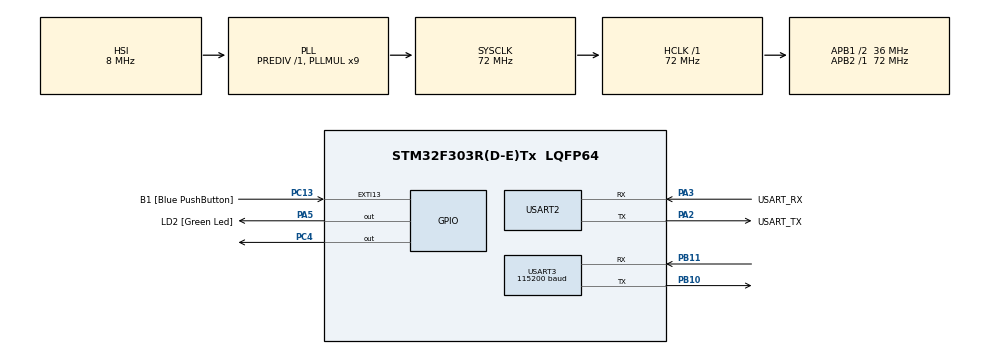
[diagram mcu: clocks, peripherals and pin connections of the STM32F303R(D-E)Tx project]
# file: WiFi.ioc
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Mcu.Family=STM32F3
Mcu.Name=STM32F303R(D-E)Tx
Mcu.Package=LQFP64
NVIC.PriorityGroup=NVIC_PRIORITYGROUP_0
NVIC.TIM1_TRG_COM_TIM17_IRQn=true\:0\:0\:false\:false\:true\:true\:true\:true
NVIC.USART3_IRQn=true\:0\:0\:false\:false\:true\:true\:true\:true
PA13.GPIO_Label=TMS
PA13.Mode=Serial_Wire
PA13.Signal=SYS_JTMS-SWDIO
PA14.GPIO_Label=TCK
PA14.Mode=Serial_Wire
PA14.Signal=SYS_JTCK-SWCLK
PA2.GPIO_Label=USART_TX
PA2.GPIO_Mode=GPIO_MODE_AF_PP
PA2.GPIO_PuPd=GPIO_NOPULL
PA2.GPIO_Speed=GPIO_SPEED_FREQ_LOW
PA2.Mode=Asynchronous
PA2.Signal=USART2_TX
PA3.GPIO_Label=USART_RX
PA3.GPIO_Mode=GPIO_MODE_AF_PP
PA3.GPIO_PuPd=GPIO_NOPULL
PA3.GPIO_Speed=GPIO_SPEED_FREQ_LOW
PA3.Mode=Asynchronous
PA3.Signal=USART2_RX
PA5.GPIO_Label=LD2 [Green Led]
PA5.GPIO_Mode=GPIO_MODE_OUTPUT_PP
PA5.GPIO_PuPd=GPIO_NOPULL
PA5.GPIO_Speed=GPIO_SPEED_FREQ_LOW
PA5.Signal=GPIO_Output
PB10.Mode=Asynchronous
PB10.Signal=USART3_TX
PB11.Mode=Asynchronous
PB11.Signal=USART3_RX
PB3.GPIO_Label=SWO
PB3.Signal=SYS_JTDO-TRACESWO
PC13.GPIO_Label=B1 [Blue PushButton]
PC13.GPIO_ModeDefaultEXTI=GPIO_MODE_IT_FALLING
PC13.Signal=GPXTI13
PC14-OSC32_IN.Mode=LSE-External-Oscillator
PC14-OSC32_IN.Signal=RCC_OSC32_IN
PC15-OSC32_OUT.Mode=LSE-External-Oscillator
PC15-OSC32_OUT.Signal=RCC_OSC32_OUT
PC4.GPIO_Speed=GPIO_SPEED_FREQ_HIGH
PC4.PinState=GPIO_PIN_SET
PC4.Signal=GPIO_Output
PF0-OSC_IN.Mode=HSE-External-Clock-Source
PF0-OSC_IN.Signal=RCC_OSC_IN
PF1-OSC_OUT.Signal=RCC_OSC_OUT
ProjectManager.HeapSize=0x200
ProjectManager.StackSize=0x400
ProjectManager.TargetToolchain=STM32CubeIDE
RCC.AHBFreq_Value=72000000
RCC.APB1CLKDivider=RCC_HCLK_DIV2
RCC.APB1Freq_Value=36000000
RCC.APB1TimFreq_Value=72000000
RCC.APB2Freq_Value=72000000
RCC.APB2TimFreq_Value=72000000
RCC.CortexFreq_Value=72000000
RCC.HCLKFreq_Value=72000000
RCC.HSE_VALUE=8000000
RCC.HSI_VALUE=8000000
RCC.PLLM=8
RCC.PLLMUL=RCC_PLL_MUL9
RCC.PLLN=336
RCC.PLLP=RCC_PLLP_DIV4
RCC.PLLQ=7
RCC.RCC_PLLsource_Clock_Source_FROM_HSE=RCC_HSE_PREDIV_DIV2
RCC.SYSCLKFreq_VALUE=72000000
RCC.SYSCLKSourceVirtual=RCC_SYSCLKSOURCE_PLLCLK
RCC.USBFreq_Value=72000000
TIM17.Period=59999
TIM17.Prescaler=11
USART2.VirtualMode-Asynchronous=VM_ASYNC
USART3.BaudRate=115200
USART3.VirtualMode-Asynchronous=VM_ASYNC
VP_TIM17_VS_ClockSourceINT.Mode=Enable_Timer
board=NUCLEO-F303RE

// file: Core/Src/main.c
/* USER CODE BEGIN Header */
/**
  ******************************************************************************
  * @file           : main.c
  * @brief          : Main program body
  ******************************************************************************
  * @attention
  *
  * Copyright (c) 2024 STMicroelectronics.
  * All rights reserved.
  *
  * This software is licensed under terms that can be found in the LICENSE file
  * in the root directory of this software component.
  * If no LICENSE file comes with this software, it is provided AS-IS.
  *
  ******************************************************************************
  */
/* USER CODE END Header */
#include "main.h"

TIM_HandleTypeDef htim17;

UART_HandleTypeDef huart2;
UART_HandleTypeDef huart3;

void SystemClock_Config(void);
static void MX_GPIO_Init(void);
static void MX_TIM17_Init(void);
static void MX_USART2_UART_Init(void);
static void MX_USART3_UART_Init(void);
/* USER CODE BEGIN PFP */
esp01s module;
/* USER CODE END PFP */

/* USER CODE BEGIN 0 */
void HAL_UART_RxCpltCallback(UART_HandleTypeDef *huart) {
	if (huart->Instance == USART3) {
		module.ESP_Interrupt();
	}
}

void HAL_TIM_PeriodElapsedCallback(TIM_HandleTypeDef *htim){
	if(htim->Instance == TIM17){
		module.ESP_Counter();
	}
}
/* USER CODE END 0 */

int main(void)
{

  /* MCU Configuration--------------------------------------------------------*/

  /* Reset of all peripherals, Initializes the Flash interface and the Systick. */
  HAL_Init();

  /* Configure the system clock */
  SystemClock_Config();

  /* Initialize all configured peripherals */
  MX_GPIO_Init();
  MX_TIM17_Init();
  MX_USART2_UART_Init();
  MX_USART3_UART_Init();
  /* USER CODE BEGIN 2 */
  HAL_TIM_Base_Start_IT(&htim17);
  /* USER CODE END 2 */

  /* Infinite loop */
  while (1)
  {
	  if(!module.atStatus)
		  module.AT_Init();
	  if(module.atStatus && !module.wifiStatus)
		  module.WiFi_Init();
  }
}

void SystemClock_Config(void)
{
  RCC_OscInitTypeDef RCC_OscInitStruct = {0};
  RCC_ClkInitTypeDef RCC_ClkInitStruct = {0};
  RCC_PeriphCLKInitTypeDef PeriphClkInit = {0};

  /** Initializes the RCC Oscillators according to the specified parameters
  * in the RCC_OscInitTypeDef structure.
  */
  RCC_OscInitStruct.OscillatorType = RCC_OSCILLATORTYPE_HSI;
  RCC_OscInitStruct.HSIState = RCC_HSI_ON;
  RCC_OscInitStruct.HSICalibrationValue = RCC_HSICALIBRATION_DEFAULT;
  RCC_OscInitStruct.PLL.PLLState = RCC_PLL_ON;
  RCC_OscInitStruct.PLL.PLLSource = RCC_PLLSOURCE_HSI;
  RCC_OscInitStruct.PLL.PLLMUL = RCC_PLL_MUL9;
  RCC_OscInitStruct.PLL.PREDIV = RCC_PREDIV_DIV1;
  if (HAL_RCC_OscConfig(&RCC_OscInitStruct) != HAL_OK)
  {
    Error_Handler();
  }

  /** Initializes the CPU, AHB and APB buses clocks
  */
  RCC_ClkInitStruct.ClockType = RCC_CLOCKTYPE_HCLK|RCC_CLOCKTYPE_SYSCLK
                              |RCC_CLOCKTYPE_PCLK1|RCC_CLOCKTYPE_PCLK2;
  RCC_ClkInitStruct.SYSCLKSource = RCC_SYSCLKSOURCE_PLLCLK;
  RCC_ClkInitStruct.AHBCLKDivider = RCC_SYSCLK_DIV1;
  RCC_ClkInitStruct.APB1CLKDivider = RCC_HCLK_DIV2;
  RCC_ClkInitStruct.APB2CLKDivider = RCC_HCLK_DIV1;

  if (HAL_RCC_ClockConfig(&RCC_ClkInitStruct, FLASH_LATENCY_2) != HAL_OK)
  {
    Error_Handler();
  }
  PeriphClkInit.PeriphClockSelection = RCC_PERIPHCLK_USART2|RCC_PERIPHCLK_USART3
                              |RCC_PERIPHCLK_TIM17;
  PeriphClkInit.Usart2ClockSelection = RCC_USART2CLKSOURCE_PCLK1;
  PeriphClkInit.Usart3ClockSelection = RCC_USART3CLKSOURCE_PCLK1;
  PeriphClkInit.Tim17ClockSelection = RCC_TIM17CLK_HCLK;
  if (HAL_RCCEx_PeriphCLKConfig(&PeriphClkInit) != HAL_OK)
  {
    Error_Handler();
  }
}

static void MX_TIM17_Init(void)
{

  htim17.Instance = TIM17;
  htim17.Init.Prescaler = 11;
  htim17.Init.CounterMode = TIM_COUNTERMODE_UP;
  htim17.Init.Period = 59999;
  htim17.Init.ClockDivision = TIM_CLOCKDIVISION_DIV1;
  htim17.Init.RepetitionCounter = 0;
  htim17.Init.AutoReloadPreload = TIM_AUTORELOAD_PRELOAD_DISABLE;
  if (HAL_TIM_Base_Init(&htim17) != HAL_OK)
  {
    Error_Handler();
  }

}

static void MX_USART2_UART_Init(void)
{

  huart2.Instance = USART2;
  huart2.Init.BaudRate = 38400;
  huart2.Init.WordLength = UART_WORDLENGTH_8B;
  huart2.Init.StopBits = UART_STOPBITS_1;
  huart2.Init.Parity = UART_PARITY_NONE;
  huart2.Init.Mode = UART_MODE_TX_RX;
  huart2.Init.HwFlowCtl = UART_HWCONTROL_NONE;
  huart2.Init.OverSampling = UART_OVERSAMPLING_16;
  huart2.Init.OneBitSampling = UART_ONE_BIT_SAMPLE_DISABLE;
  huart2.AdvancedInit.AdvFeatureInit = UART_ADVFEATURE_NO_INIT;
  if (HAL_UART_Init(&huart2) != HAL_OK)
  {
    Error_Handler();
  }

}

static void MX_USART3_UART_Init(void)
{

  huart3.Instance = USART3;
  huart3.Init.BaudRate = 115200;
  huart3.Init.WordLength = UART_WORDLENGTH_8B;
  huart3.Init.StopBits = UART_STOPBITS_1;
  huart3.Init.Parity = UART_PARITY_NONE;
  huart3.Init.Mode = UART_MODE_TX_RX;
  huart3.Init.HwFlowCtl = UART_HWCONTROL_NONE;
  huart3.Init.OverSampling = UART_OVERSAMPLING_16;
  huart3.Init.OneBitSampling = UART_ONE_BIT_SAMPLE_DISABLE;
  huart3.AdvancedInit.AdvFeatureInit = UART_ADVFEATURE_NO_INIT;
  if (HAL_UART_Init(&huart3) != HAL_OK)
  {
    Error_Handler();
  }

}

static void MX_GPIO_Init(void)
{
  GPIO_InitTypeDef GPIO_InitStruct = {0};

  /* GPIO Ports Clock Enable */
  __HAL_RCC_GPIOC_CLK_ENABLE();
  __HAL_RCC_GPIOF_CLK_ENABLE();
  __HAL_RCC_GPIOA_CLK_ENABLE();
  __HAL_RCC_GPIOB_CLK_ENABLE();

  /*Configure GPIO pin Output Level */
  HAL_GPIO_WritePin(LD2_GPIO_Port, LD2_Pin, GPIO_PIN_RESET);

  /*Configure GPIO pin Output Level */
  HAL_GPIO_WritePin(GPIOC, GPIO_PIN_4, GPIO_PIN_SET);

  /*Configure GPIO pin : B1_Pin */
  GPIO_InitStruct.Pin = B1_Pin;
  GPIO_InitStruct.Mode = GPIO_MODE_IT_FALLING;
  GPIO_InitStruct.Pull = GPIO_NOPULL;
  HAL_GPIO_Init(B1_GPIO_Port, &GPIO_InitStruct);

  /*Configure GPIO pin : LD2_Pin */
  GPIO_InitStruct.Pin = LD2_Pin;
  GPIO_InitStruct.Mode = GPIO_MODE_OUTPUT_PP;
  GPIO_InitStruct.Pull = GPIO_NOPULL;
  GPIO_InitStruct.Speed = GPIO_SPEED_FREQ_LOW;
  HAL_GPIO_Init(LD2_GPIO_Port, &GPIO_InitStruct);

  /*Configure GPIO pin : PC4 */
  GPIO_InitStruct.Pin = GPIO_PIN_4;
  GPIO_InitStruct.Mode = GPIO_MODE_OUTPUT_PP;
  GPIO_InitStruct.Pull = GPIO_NOPULL;
  GPIO_InitStruct.Speed = GPIO_SPEED_FREQ_HIGH;
  HAL_GPIO_Init(GPIOC, &GPIO_InitStruct);

}

void Error_Handler(void)
{
  __disable_irq();
  while (1)
  {
  }
}
